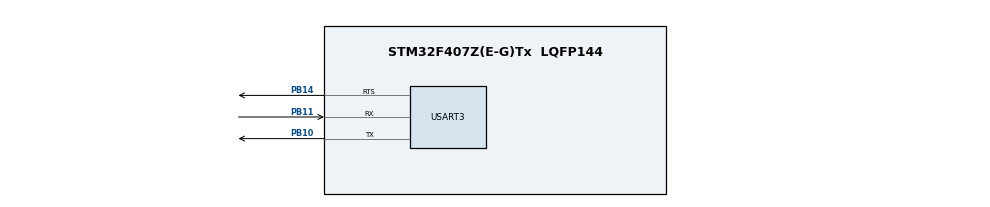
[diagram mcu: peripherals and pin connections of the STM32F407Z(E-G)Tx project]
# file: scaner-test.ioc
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Dma.Request0=USART3_RX
Dma.USART3_RX.0.Direction=DMA_PERIPH_TO_MEMORY
Dma.USART3_RX.0.FIFOMode=DMA_FIFOMODE_DISABLE
Dma.USART3_RX.0.Instance=DMA1_Stream1
Dma.USART3_RX.0.MemDataAlignment=DMA_MDATAALIGN_BYTE
Dma.USART3_RX.0.MemInc=DMA_MINC_ENABLE
Dma.USART3_RX.0.Mode=DMA_NORMAL
Dma.USART3_RX.0.PeriphDataAlignment=DMA_PDATAALIGN_BYTE
Dma.USART3_RX.0.PeriphInc=DMA_PINC_DISABLE
Dma.USART3_RX.0.Priority=DMA_PRIORITY_LOW
Mcu.Family=STM32F4
Mcu.Name=STM32F407Z(E-G)Tx
Mcu.Package=LQFP144
NVIC.DMA1_Stream1_IRQn=true\:9\:0\:true\:false\:true\:false\:true
NVIC.PriorityGroup=NVIC_PRIORITYGROUP_4
NVIC.USART3_IRQn=true\:7\:0\:true\:false\:true\:true\:true
PB10.Mode=Asynchronous
PB10.Signal=USART3_TX
PB11.Mode=Asynchronous
PB11.Signal=USART3_RX
PB14.Mode=RTS_Only
PB14.Signal=USART3_RTS
ProjectManager.HeapSize=0x200
ProjectManager.StackSize=0x400
ProjectManager.TargetToolchain=Makefile
RCC.48MHZClocksFreq_Value=84000000
RCC.AHBFreq_Value=168000000
RCC.APB1CLKDivider=RCC_HCLK_DIV4
RCC.APB1Freq_Value=42000000
RCC.APB1TimFreq_Value=84000000
RCC.APB2CLKDivider=RCC_HCLK_DIV2
RCC.APB2Freq_Value=84000000
RCC.APB2TimFreq_Value=168000000
RCC.CortexFreq_Value=168000000
RCC.HCLKFreq_Value=168000000
RCC.HSE_VALUE=25000000
RCC.HSI_VALUE=16000000
RCC.LSE_VALUE=32768
RCC.PLLM=8
RCC.PLLN=168
RCC.SYSCLKFreq_VALUE=168000000
RCC.SYSCLKSource=RCC_SYSCLKSOURCE_PLLCLK
RCC.VCOOutputFreq_Value=336000000
USART3.VirtualMode=VM_ASYNC
board=custom

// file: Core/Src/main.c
/* USER CODE BEGIN Header */
/**
  ******************************************************************************
  * @file           : main.c
  * @brief          : Main program body
  ******************************************************************************
  * @attention
  *
  * <h2><center>&copy; Copyright (c) 2021 STMicroelectronics.
  * All rights reserved.</center></h2>
  *
  * This software component is licensed by ST under BSD 3-Clause license,
  * the "License"; You may not use this file except in compliance with the
  * License. You may obtain a copy of the License at:
  *                        opensource.org/licenses/BSD-3-Clause
  *
  ******************************************************************************
  */
/* USER CODE END Header */
#include "main.h"

void SystemClock_Config(void);
static void MX_GPIO_Init(void);
static void MX_DMA_Init(void);
static void MX_USART3_UART_Init(void);

/* USER CODE BEGIN 0 */
uint8_t usart1DMABuf[14] = {0};

void USART1DMAConfig()
{
  LL_DMA_SetMemoryAddress(DMA1, LL_DMA_STREAM_1, (uint32_t)usart1DMABuf);
  LL_DMA_SetPeriphAddress(DMA1, LL_DMA_STREAM_1, LL_USART_DMA_GetRegAddr(USART3));
  LL_DMA_SetDataLength(DMA1, LL_DMA_STREAM_1, 14);
  LL_DMA_EnableStream(DMA1, LL_DMA_STREAM_1);
  LL_USART_EnableIT_IDLE(USART3);
  LL_USART_EnableDMAReq_RX(USART3);
}
/* USER CODE END 0 */

int main(void)
{

  /* MCU Configuration--------------------------------------------------------*/

  /* Reset of all peripherals, Initializes the Flash interface and the Systick. */
  HAL_Init();

  /* Configure the system clock */
  SystemClock_Config();

  /* Initialize all configured peripherals */
  MX_GPIO_Init();
  MX_DMA_Init();
  MX_USART3_UART_Init();
  /* USER CODE BEGIN 2 */
  USART1DMAConfig();
  /* USER CODE END 2 */

  /* Infinite loop */
  while (1)
  {

  }
}

void SystemClock_Config(void)
{
  LL_FLASH_SetLatency(LL_FLASH_LATENCY_5);
  while(LL_FLASH_GetLatency()!= LL_FLASH_LATENCY_5)
  {
  }
  LL_PWR_SetRegulVoltageScaling(LL_PWR_REGU_VOLTAGE_SCALE1);
  LL_RCC_HSI_SetCalibTrimming(16);
  LL_RCC_HSI_Enable();

   /* Wait till HSI is ready */
  while(LL_RCC_HSI_IsReady() != 1)
  {

  }
  LL_RCC_PLL_ConfigDomain_SYS(LL_RCC_PLLSOURCE_HSI, LL_RCC_PLLM_DIV_8, 168, LL_RCC_PLLP_DIV_2);
  LL_RCC_PLL_Enable();

   /* Wait till PLL is ready */
  while(LL_RCC_PLL_IsReady() != 1)
  {

  }
  LL_RCC_SetAHBPrescaler(LL_RCC_SYSCLK_DIV_1);
  LL_RCC_SetAPB1Prescaler(LL_RCC_APB1_DIV_4);
  LL_RCC_SetAPB2Prescaler(LL_RCC_APB2_DIV_2);
  LL_RCC_SetSysClkSource(LL_RCC_SYS_CLKSOURCE_PLL);

   /* Wait till System clock is ready */
  while(LL_RCC_GetSysClkSource() != LL_RCC_SYS_CLKSOURCE_STATUS_PLL)
  {

  }
  LL_SetSystemCoreClock(168000000);

   /* Update the time base */
  if (HAL_InitTick (TICK_INT_PRIORITY) != HAL_OK)
  {
    Error_Handler();
  }
}

static void MX_USART3_UART_Init(void)
{

  LL_USART_InitTypeDef USART_InitStruct = {0};

  LL_GPIO_InitTypeDef GPIO_InitStruct = {0};

  /* Peripheral clock enable */
  LL_APB1_GRP1_EnableClock(LL_APB1_GRP1_PERIPH_USART3);

  LL_AHB1_GRP1_EnableClock(LL_AHB1_GRP1_PERIPH_GPIOB);
  /**USART3 GPIO Configuration
  PB10   ------> USART3_TX
  PB11   ------> USART3_RX
  PB14   ------> USART3_RTS
  */
  GPIO_InitStruct.Pin = LL_GPIO_PIN_10|LL_GPIO_PIN_11|LL_GPIO_PIN_14;
  GPIO_InitStruct.Mode = LL_GPIO_MODE_ALTERNATE;
  GPIO_InitStruct.Speed = LL_GPIO_SPEED_FREQ_VERY_HIGH;
  GPIO_InitStruct.OutputType = LL_GPIO_OUTPUT_PUSHPULL;
  GPIO_InitStruct.Pull = LL_GPIO_PULL_NO;
  GPIO_InitStruct.Alternate = LL_GPIO_AF_7;
  LL_GPIO_Init(GPIOB, &GPIO_InitStruct);

  /* USART3 DMA Init */

  /* USART3_RX Init */
  LL_DMA_SetChannelSelection(DMA1, LL_DMA_STREAM_1, LL_DMA_CHANNEL_4);

  LL_DMA_SetDataTransferDirection(DMA1, LL_DMA_STREAM_1, LL_DMA_DIRECTION_PERIPH_TO_MEMORY);

  LL_DMA_SetStreamPriorityLevel(DMA1, LL_DMA_STREAM_1, LL_DMA_PRIORITY_LOW);

  LL_DMA_SetMode(DMA1, LL_DMA_STREAM_1, LL_DMA_MODE_NORMAL);

  LL_DMA_SetPeriphIncMode(DMA1, LL_DMA_STREAM_1, LL_DMA_PERIPH_NOINCREMENT);

  LL_DMA_SetMemoryIncMode(DMA1, LL_DMA_STREAM_1, LL_DMA_MEMORY_INCREMENT);

  LL_DMA_SetPeriphSize(DMA1, LL_DMA_STREAM_1, LL_DMA_PDATAALIGN_BYTE);

  LL_DMA_SetMemorySize(DMA1, LL_DMA_STREAM_1, LL_DMA_MDATAALIGN_BYTE);

  LL_DMA_DisableFifoMode(DMA1, LL_DMA_STREAM_1);

  /* USART3 interrupt Init */
  NVIC_SetPriority(USART3_IRQn, NVIC_EncodePriority(NVIC_GetPriorityGrouping(),7, 0));
  NVIC_EnableIRQ(USART3_IRQn);

  USART_InitStruct.BaudRate = 115200;
  USART_InitStruct.DataWidth = LL_USART_DATAWIDTH_8B;
  USART_InitStruct.StopBits = LL_USART_STOPBITS_1;
  USART_InitStruct.Parity = LL_USART_PARITY_NONE;
  USART_InitStruct.TransferDirection = LL_USART_DIRECTION_TX_RX;
  USART_InitStruct.HardwareFlowControl = LL_USART_HWCONTROL_RTS;
  USART_InitStruct.OverSampling = LL_USART_OVERSAMPLING_16;
  LL_USART_Init(USART3, &USART_InitStruct);
  LL_USART_ConfigAsyncMode(USART3);
  LL_USART_Enable(USART3);

}

static void MX_DMA_Init(void)
{

  /* Init with LL driver */
  /* DMA controller clock enable */
  LL_AHB1_GRP1_EnableClock(LL_AHB1_GRP1_PERIPH_DMA1);

  /* DMA interrupt init */
  /* DMA1_Stream1_IRQn interrupt configuration */
  NVIC_SetPriority(DMA1_Stream1_IRQn, NVIC_EncodePriority(NVIC_GetPriorityGrouping(),9, 0));
  NVIC_EnableIRQ(DMA1_Stream1_IRQn);

}

static void MX_GPIO_Init(void)
{

  /* GPIO Ports Clock Enable */
  __HAL_RCC_GPIOB_CLK_ENABLE();

}

void Error_Handler(void)
{
}

/************************ (C) COPYRIGHT STMicroelectronics *****END OF FILE****/
